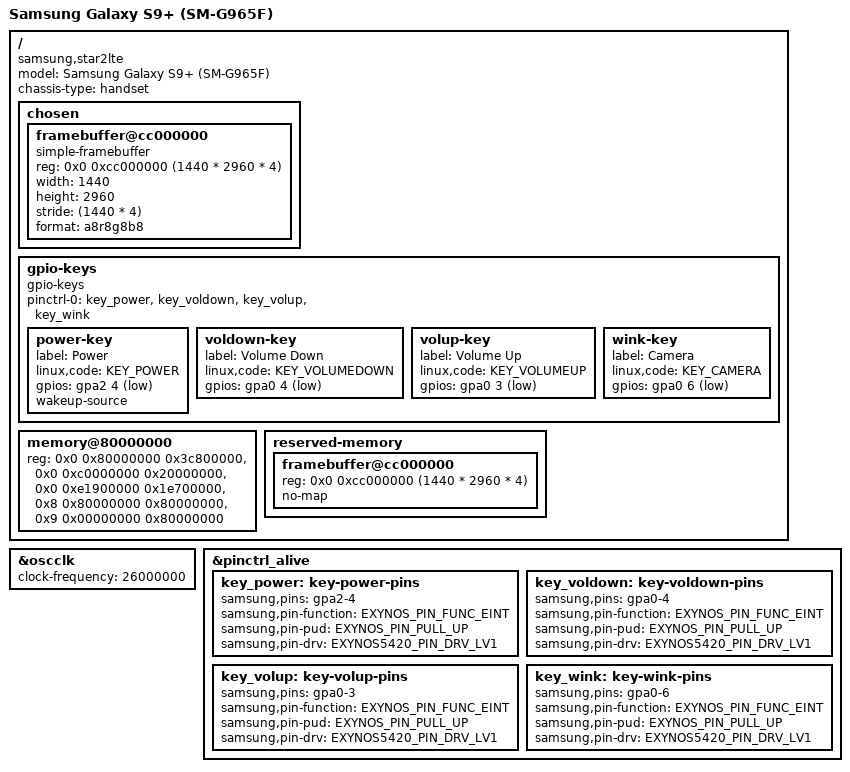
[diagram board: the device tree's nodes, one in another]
// SPDX-License-Identifier: GPL-2.0 OR BSD-3-Clause
/*
 * Samsung Galaxy S9+ (star2lte/SM-G965F) device tree source
 *
 * Copyright (c) 2024 Markuss Broks <markuss.broks@gmail.com>
 * Copyright (c) 2024 Maksym Holovach <nergzd@nergzd723.xyz>
 */

/dts-v1/;
#include "exynos9810.dtsi"
#include <dt-bindings/gpio/gpio.h>
#include <dt-bindings/input/input.h>

/ {
	model = "Samsung Galaxy S9+ (SM-G965F)";
	compatible = "samsung,star2lte", "samsung,exynos9810";
	chassis-type = "handset";

	chosen {
		#address-cells = <2>;
		#size-cells = <1>;
		ranges;

		framebuffer@cc000000 {
			compatible = "simple-framebuffer";
			reg = <0x0 0xcc000000 (1440 * 2960 * 4)>;
			width = <1440>;
			height = <2960>;
			stride = <(1440 * 4)>;
			format = "a8r8g8b8";
		};
	};

	gpio-keys {
		compatible = "gpio-keys";

		pinctrl-0 = <&key_power &key_voldown &key_volup &key_wink>;
		pinctrl-names = "default";

		power-key {
			label = "Power";
			linux,code = <KEY_POWER>;
			gpios = <&gpa2 4 GPIO_ACTIVE_LOW>;
			wakeup-source;
		};

		voldown-key {
			label = "Volume Down";
			linux,code = <KEY_VOLUMEDOWN>;
			gpios = <&gpa0 4 GPIO_ACTIVE_LOW>;
		};

		volup-key {
			label = "Volume Up";
			linux,code = <KEY_VOLUMEUP>;
			gpios = <&gpa0 3 GPIO_ACTIVE_LOW>;
		};

		/* In stock firmware used for assistant. Map it as a camera button for now */
		wink-key {
			label = "Camera";
			linux,code = <KEY_CAMERA>;
			gpios = <&gpa0 6 GPIO_ACTIVE_LOW>;
		};
	};

	/*
	 * Samsung Galaxy S9+ is equipped with 6 GiB LPDDR4X RAM, laid out
	 * across five contiguous physical regions. Addresses are taken
	 * verbatim from the downstream (Android) device tree and confirmed
	 * against the Exynos 9810 memory map.
	 *
	 * Region 0: 0x0_8000_0000 – 0x0_BC7F_FFFF  (~972 MiB)
	 * Region 1: 0x0_C000_0000 – 0x0_DFFF_FFFF  ( 512 MiB)
	 * Region 2: 0x0_E190_0000 – 0x0_FFFF_FFFF  (~488 MiB)
	 * Region 3: 0x8_8000_0000 – 0x8_FFFF_FFFF  (2048 MiB)
	 * Region 4: 0x9_0000_0000 – 0x9_7FFF_FFFF  (2048 MiB)
	 *
	 * Total usable: ~6 GiB (some headroom is consumed by reserved-memory
	 * regions declared in the firmware / TF-A; the kernel learns the
	 * exact usable map from those reservations at boot time).
	 */
	memory@80000000 {
		device_type = "memory";
		reg = <0x0 0x80000000 0x3c800000>,
		      <0x0 0xc0000000 0x20000000>,
		      <0x0 0xe1900000 0x1e700000>,
		      <0x8 0x80000000 0x80000000>,
		      <0x9 0x00000000 0x80000000>;
	};

	reserved-memory {
		#address-cells = <2>;
		#size-cells = <1>;
		ranges;

		framebuffer@cc000000 {
			reg = <0x0 0xcc000000 (1440 * 2960 * 4)>;
			no-map;
		};
	};
};

&oscclk {
	clock-frequency = <26000000>;
};

&pinctrl_alive {
	key_power: key-power-pins {
		samsung,pins = "gpa2-4";
		samsung,pin-function = <EXYNOS_PIN_FUNC_EINT>;
		samsung,pin-pud = <EXYNOS_PIN_PULL_UP>;
		samsung,pin-drv = <EXYNOS5420_PIN_DRV_LV1>;
	};

	key_voldown: key-voldown-pins {
		samsung,pins = "gpa0-4";
		samsung,pin-function = <EXYNOS_PIN_FUNC_EINT>;
		samsung,pin-pud = <EXYNOS_PIN_PULL_UP>;
		samsung,pin-drv = <EXYNOS5420_PIN_DRV_LV1>;
	};

	key_volup: key-volup-pins {
		samsung,pins = "gpa0-3";
		samsung,pin-function = <EXYNOS_PIN_FUNC_EINT>;
		samsung,pin-pud = <EXYNOS_PIN_PULL_UP>;
		samsung,pin-drv = <EXYNOS5420_PIN_DRV_LV1>;
	};

	key_wink: key-wink-pins {
		samsung,pins = "gpa0-6";
		samsung,pin-function = <EXYNOS_PIN_FUNC_EINT>;
		samsung,pin-pud = <EXYNOS_PIN_PULL_UP>;
		samsung,pin-drv = <EXYNOS5420_PIN_DRV_LV1>;
	};
};
